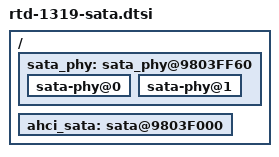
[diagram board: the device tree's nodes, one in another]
/* PLEASE include this file inside a node */

#include "rtd-13xx-sata.dtsi"

/ {
	sata_phy: sata_phy@9803FF60 {
		status = "okay";
		sata-phy@0 {
			status = "okay";
		};
		sata-phy@1 {
			status = "okay";
		};
	};

	ahci_sata: sata@9803F000 {
		status = "okay";
	};
};
